AUTOSAR XML (schema 4-2-2)
package /STELLANTIS/EPT/ASWCs
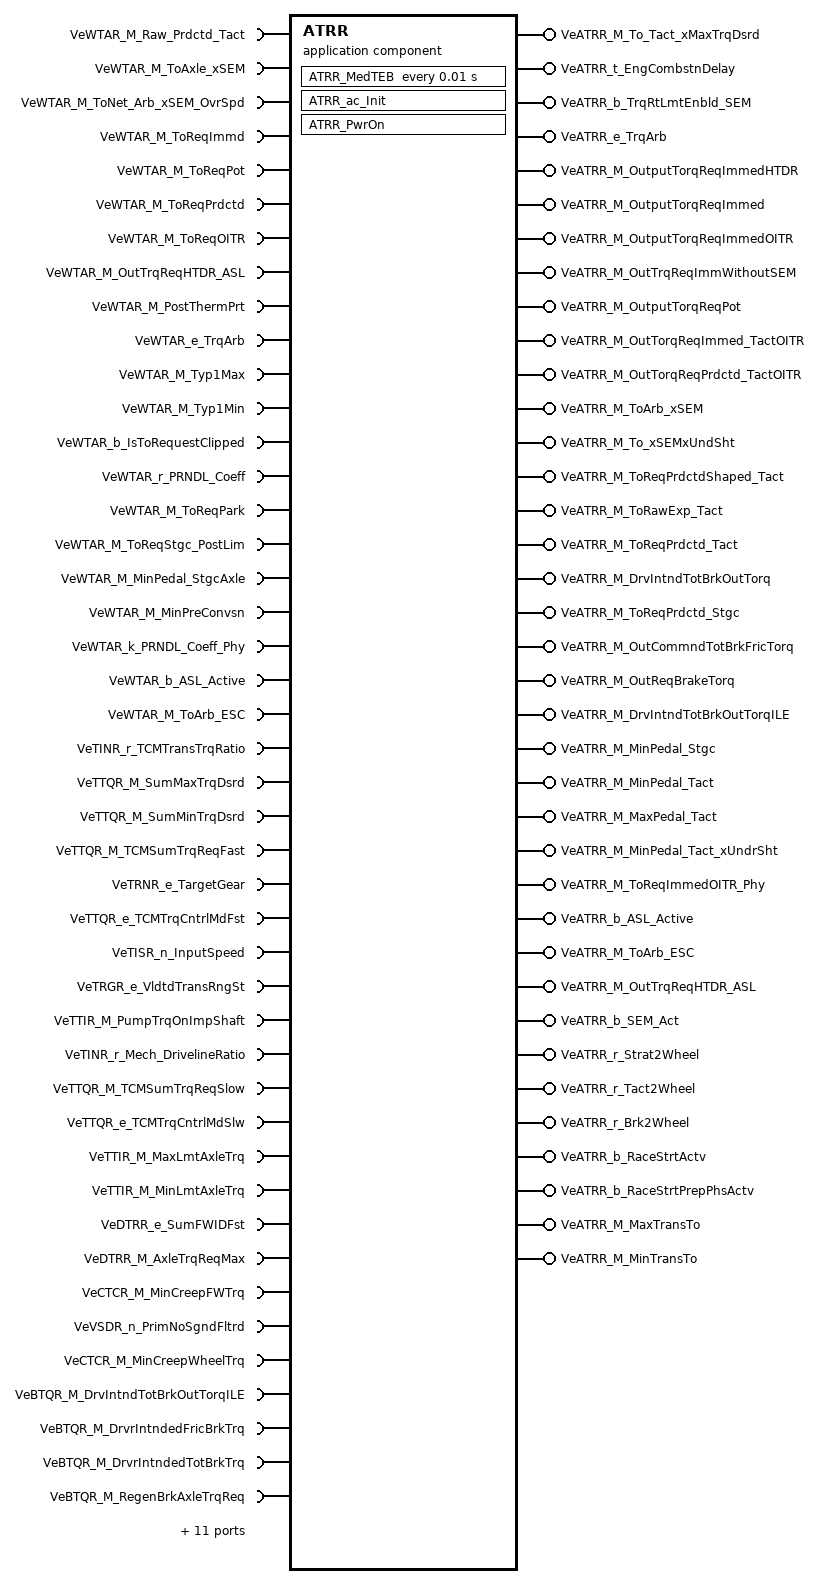
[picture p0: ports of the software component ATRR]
  application sw component type ATRR
    50 x require port:
      VeWTAR_M_Raw_Prdctd_Tact: nonqueued-receiver-com-spec{data-element=Value, init-value=0}, required-interface=VeWTAR_M_Raw_Prdctd_Tact
      VeWTAR_M_ToAxle_xSEM: nonqueued-receiver-com-spec{data-element=Value, init-value=0}, required-interface=VeWTAR_M_ToAxle_xSEM
      VeWTAR_M_ToNet_Arb_xSEM_OvrSpd: nonqueued-receiver-com-spec{data-element=Value, init-value=0}, required-interface=VeWTAR_M_ToNet_Arb_xSEM_OvrSpd
      VeWTAR_M_ToReqImmd: nonqueued-receiver-com-spec{data-element=Value, init-value=0}, required-interface=VeWTAR_M_ToReqImmd
      VeWTAR_M_ToReqPot: nonqueued-receiver-com-spec{data-element=Value, init-value=0}, required-interface=VeWTAR_M_ToReqPot
      VeWTAR_M_ToReqPrdctd: nonqueued-receiver-com-spec{data-element=Value, init-value=0}, required-interface=VeWTAR_M_ToReqPrdctd
      VeWTAR_M_ToReqOITR: nonqueued-receiver-com-spec{data-element=Value, init-value=0}, required-interface=VeWTAR_M_ToReqOITR
      VeWTAR_M_OutTrqReqHTDR_ASL: nonqueued-receiver-com-spec{data-element=Value, init-value=0}, required-interface=VeWTAR_M_OutTrqReqHTDR_ASL
      VeWTAR_M_PostThermPrt: nonqueued-receiver-com-spec{data-element=Value, init-value=0}, required-interface=VeWTAR_M_PostThermPrt
      VeWTAR_e_TrqArb: nonqueued-receiver-com-spec{data-element=Value, init-value=CeWTAR_e_ECM_TorqReqst}, required-interface=VeWTAR_e_TrqArb
      VeWTAR_M_Typ1Max: nonqueued-receiver-com-spec{data-element=Value, init-value=0}, required-interface=VeWTAR_M_Typ1Max
      VeWTAR_M_Typ1Min: nonqueued-receiver-com-spec{data-element=Value, init-value=0}, required-interface=VeWTAR_M_Typ1Min
      VeWTAR_b_IsToRequestClipped: nonqueued-receiver-com-spec{data-element=Value, init-value=0}, required-interface=VeWTAR_b_IsToRequestClipped
      VeWTAR_r_PRNDL_Coeff: nonqueued-receiver-com-spec{data-element=Value, init-value=0}, required-interface=VeWTAR_r_PRNDL_Coeff
      VeWTAR_M_ToReqPark: nonqueued-receiver-com-spec{data-element=Value, init-value=0}, required-interface=VeWTAR_M_ToReqPark
      VeWTAR_M_ToReqStgc_PostLim: nonqueued-receiver-com-spec{data-element=Value, init-value=0}, required-interface=VeWTAR_M_ToReqStgc_PostLim
      VeWTAR_M_MinPedal_StgcAxle: nonqueued-receiver-com-spec{data-element=Value, init-value=0}, required-interface=VeWTAR_M_MinPedal_StgcAxle
      VeWTAR_M_MinPreConvsn: nonqueued-receiver-com-spec{data-element=Value, init-value=0}, required-interface=VeWTAR_M_MinPreConvsn
      VeWTAR_k_PRNDL_Coeff_Phy: nonqueued-receiver-com-spec{data-element=Value, init-value=0}, required-interface=VeWTAR_k_PRNDL_Coeff_Phy
      VeWTAR_b_ASL_Active: nonqueued-receiver-com-spec{data-element=Value, init-value=0}, required-interface=VeWTAR_b_ASL_Active
      VeWTAR_M_ToArb_ESC: nonqueued-receiver-com-spec{data-element=Value, init-value=0}, required-interface=VeWTAR_M_ToArb_ESC
      VeTINR_r_TCMTransTrqRatio: nonqueued-receiver-com-spec{data-element=Value, init-value=0}, required-interface=VeTINR_r_TCMTransTrqRatio
      VeTTQR_M_SumMaxTrqDsrd: nonqueued-receiver-com-spec{data-element=Value, init-value=0}, required-interface=VeTTQR_M_SumMaxTrqDsrd
      VeTTQR_M_SumMinTrqDsrd: nonqueued-receiver-com-spec{data-element=Value, init-value=0}, required-interface=VeTTQR_M_SumMinTrqDsrd
      VeTTQR_M_TCMSumTrqReqFast: nonqueued-receiver-com-spec{data-element=Value, init-value=0}, required-interface=VeTTQR_M_TCMSumTrqReqFast
      VeTRNR_e_TargetGear: nonqueued-receiver-com-spec{data-element=Value, init-value=CeTRNR_e_Neutral}, required-interface=VeTRNR_e_TargetGear
      VeTTQR_e_TCMTrqCntrlMdFst: nonqueued-receiver-com-spec{data-element=Value, init-value=CeTINR_e_None}, required-interface=VeTTQR_e_TCMTrqCntrlMdFst
      VeTISR_n_InputSpeed: nonqueued-receiver-com-spec{data-element=Value, init-value=0}, required-interface=VeTISR_n_InputSpeed
      VeTRGR_e_VldtdTransRngSt: nonqueued-receiver-com-spec{data-element=Value, init-value=CeTRGR_e_NoSelectionAvailable}, required-interface=VeTRGR_e_VldtdTransRngSt
      VeTTIR_M_PumpTrqOnImpShaft: nonqueued-receiver-com-spec{data-element=Value, init-value=0}, required-interface=VeTTIR_M_PumpTrqOnImpShaft
      VeTINR_r_Mech_DrivelineRatio: nonqueued-receiver-com-spec{data-element=Value, init-value=0}, required-interface=VeTINR_r_Mech_DrivelineRatio
      VeTTQR_M_TCMSumTrqReqSlow: nonqueued-receiver-com-spec{data-element=Value, init-value=0}, required-interface=VeTTQR_M_TCMSumTrqReqSlow
      VeTTQR_e_TCMTrqCntrlMdSlw: nonqueued-receiver-com-spec{data-element=Value, init-value=CeTINR_e_None}, required-interface=VeTTQR_e_TCMTrqCntrlMdSlw
      VeTTIR_M_MaxLmtAxleTrq: nonqueued-receiver-com-spec{data-element=Value, init-value=0}, required-interface=VeTTIR_M_MaxLmtAxleTrq
      VeTTIR_M_MinLmtAxleTrq: nonqueued-receiver-com-spec{data-element=Value, init-value=0}, required-interface=VeTTIR_M_MinLmtAxleTrq
      VeDTRR_e_SumFWIDFst: nonqueued-receiver-com-spec{data-element=Value, init-value=CeDTRR_e_Potential}, required-interface=VeDTRR_e_SumFWIDFst
      VeDTRR_M_AxleTrqReqMax: nonqueued-receiver-com-spec{data-element=Value, init-value=0}, required-interface=VeDTRR_M_AxleTrqReqMax
      VeCTCR_M_MinCreepFWTrq: nonqueued-receiver-com-spec{data-element=Value, init-value=0}, required-interface=VeCTCR_M_MinCreepFWTrq
      VeVSDR_n_PrimNoSgndFltrd: nonqueued-receiver-com-spec{data-element=Value, init-value=0}, required-interface=VeVSDR_n_PrimNoSgndFltrd
      VeCTCR_M_MinCreepWheelTrq: nonqueued-receiver-com-spec{data-element=Value, init-value=0}, required-interface=VeCTCR_M_MinCreepWheelTrq
      VeBTQR_M_DrvIntndTotBrkOutTorqILE: nonqueued-receiver-com-spec{data-element=Value, init-value=0}, required-interface=VeBTQR_M_DrvIntndTotBrkOutTorqILE
      VeBTQR_M_DrvrIntndedFricBrkTrq: nonqueued-receiver-com-spec{data-element=Value, init-value=0}, required-interface=VeBTQR_M_DrvrIntndedFricBrkTrq
      VeBTQR_M_DrvrIntndedTotBrkTrq: nonqueued-receiver-com-spec{data-element=Value, init-value=0}, required-interface=VeBTQR_M_DrvrIntndedTotBrkTrq
      VeBTQR_M_RegenBrkAxleTrqReq: nonqueued-receiver-com-spec{data-element=Value, init-value=0}, required-interface=VeBTQR_M_RegenBrkAxleTrqReq
      VeFWDR_r_TCaseRatio: nonqueued-receiver-com-spec{data-element=Value, init-value=0}, required-interface=VeFWDR_r_TCaseRatio
      VeFWDR_r_Axle_Ratio: nonqueued-receiver-com-spec{data-element=Value, init-value=0}, required-interface=VeFWDR_r_Axle_Ratio
      VeSCCR_M_OutputTorqueLimit: nonqueued-receiver-com-spec{data-element=Value, init-value=0}, required-interface=VeSCCR_M_OutputTorqueLimit
      VeSCCR_M_ESCSumMax: nonqueued-receiver-com-spec{data-element=Value, init-value=0}, required-interface=VeSCCR_M_ESCSumMax
      VeSCCR_M_ESCSumMin: nonqueued-receiver-com-spec{data-element=Value, init-value=0}, required-interface=VeSCCR_M_ESCSumMin
      VeCTCR_M_MinCreepFWTrqTgt: nonqueued-receiver-com-spec{data-element=Value, init-value=0}, required-interface=VeCTCR_M_MinCreepFWTrqTgt
    37 x provide port:
      VeATRR_M_To_Tact_xMaxTrqDsrd: nonqueued-sender-com-spec{data-element=Value, init-value=0}, provided-interface=VeATRR_M_To_Tact_xMaxTrqDsrd
      VeATRR_t_EngCombstnDelay: nonqueued-sender-com-spec{data-element=Value, init-value=0}, provided-interface=VeATRR_t_EngCombstnDelay
      VeATRR_b_TrqRtLmtEnbld_SEM: nonqueued-sender-com-spec{data-element=Value, init-value=0}, provided-interface=VeATRR_b_TrqRtLmtEnbld_SEM
      VeATRR_e_TrqArb: nonqueued-sender-com-spec{data-element=Value, init-value=CeWTAR_e_ECM_TorqReqst}, provided-interface=VeATRR_e_TrqArb
      VeATRR_M_OutputTorqReqImmedHTDR: nonqueued-sender-com-spec{data-element=Value, init-value=0}, provided-interface=VeATRR_M_OutputTorqReqImmedHTDR
      VeATRR_M_OutputTorqReqImmed: nonqueued-sender-com-spec{data-element=Value, init-value=0}, provided-interface=VeATRR_M_OutputTorqReqImmed
      VeATRR_M_OutputTorqReqImmedOITR: nonqueued-sender-com-spec{data-element=Value, init-value=0}, provided-interface=VeATRR_M_OutputTorqReqImmedOITR
      VeATRR_M_OutTrqReqImmWithoutSEM: nonqueued-sender-com-spec{data-element=Value, init-value=0}, provided-interface=VeATRR_M_OutTrqReqImmWithoutSEM
      VeATRR_M_OutputTorqReqPot: nonqueued-sender-com-spec{data-element=Value, init-value=0}, provided-interface=VeATRR_M_OutputTorqReqPot
      VeATRR_M_OutTorqReqImmed_TactOITR: nonqueued-sender-com-spec{data-element=Value, init-value=0}, provided-interface=VeATRR_M_OutTorqReqImmed_TactOITR
      VeATRR_M_OutTorqReqPrdctd_TactOITR: nonqueued-sender-com-spec{data-element=Value, init-value=0}, provided-interface=VeATRR_M_OutTorqReqPrdctd_TactOITR
      VeATRR_M_ToArb_xSEM: nonqueued-sender-com-spec{data-element=Value, init-value=0}, provided-interface=VeATRR_M_ToArb_xSEM
      VeATRR_M_To_xSEMxUndSht: nonqueued-sender-com-spec{data-element=Value, init-value=0}, provided-interface=VeATRR_M_To_xSEMxUndSht
      VeATRR_M_ToReqPrdctdShaped_Tact: nonqueued-sender-com-spec{data-element=Value, init-value=0}, provided-interface=VeATRR_M_ToReqPrdctdShaped_Tact
      VeATRR_M_ToRawExp_Tact: nonqueued-sender-com-spec{data-element=Value, init-value=0}, provided-interface=VeATRR_M_ToRawExp_Tact
      VeATRR_M_ToReqPrdctd_Tact: nonqueued-sender-com-spec{data-element=Value, init-value=0}, provided-interface=VeATRR_M_ToReqPrdctd_Tact
      VeATRR_M_DrvIntndTotBrkOutTorq: nonqueued-sender-com-spec{data-element=Value, init-value=0}, provided-interface=VeATRR_M_DrvIntndTotBrkOutTorq
      VeATRR_M_ToReqPrdctd_Stgc: nonqueued-sender-com-spec{data-element=Value, init-value=0}, provided-interface=VeATRR_M_ToReqPrdctd_Stgc
      VeATRR_M_OutCommndTotBrkFricTorq: nonqueued-sender-com-spec{data-element=Value, init-value=0}, provided-interface=VeATRR_M_OutCommndTotBrkFricTorq
      VeATRR_M_OutReqBrakeTorq: nonqueued-sender-com-spec{data-element=Value, init-value=0}, provided-interface=VeATRR_M_OutReqBrakeTorq
      VeATRR_M_DrvIntndTotBrkOutTorqILE: nonqueued-sender-com-spec{data-element=Value, init-value=0}, provided-interface=VeATRR_M_DrvIntndTotBrkOutTorqILE
      VeATRR_M_MinPedal_Stgc: nonqueued-sender-com-spec{data-element=Value, init-value=0}, provided-interface=VeATRR_M_MinPedal_Stgc
      VeATRR_M_MinPedal_Tact: nonqueued-sender-com-spec{data-element=Value, init-value=0}, provided-interface=VeATRR_M_MinPedal_Tact
      VeATRR_M_MaxPedal_Tact: nonqueued-sender-com-spec{data-element=Value, init-value=0}, provided-interface=VeATRR_M_MaxPedal_Tact
      VeATRR_M_MinPedal_Tact_xUndrSht: nonqueued-sender-com-spec{data-element=Value, init-value=0}, provided-interface=VeATRR_M_MinPedal_Tact_xUndrSht
      VeATRR_M_ToReqImmedOITR_Phy: nonqueued-sender-com-spec{data-element=Value, init-value=0}, provided-interface=VeATRR_M_ToReqImmedOITR_Phy
      VeATRR_b_ASL_Active: nonqueued-sender-com-spec{data-element=Value, init-value=0}, provided-interface=VeATRR_b_ASL_Active
      VeATRR_M_ToArb_ESC: nonqueued-sender-com-spec{data-element=Value, init-value=0}, provided-interface=VeATRR_M_ToArb_ESC
      VeATRR_M_OutTrqReqHTDR_ASL: nonqueued-sender-com-spec{data-element=Value, init-value=0}, provided-interface=VeATRR_M_OutTrqReqHTDR_ASL
      VeATRR_b_SEM_Act: nonqueued-sender-com-spec{data-element=Value, init-value=0}, provided-interface=VeATRR_b_SEM_Act
      VeATRR_r_Strat2Wheel: nonqueued-sender-com-spec{data-element=Value, init-value=0}, provided-interface=VeATRR_r_Strat2Wheel
      VeATRR_r_Tact2Wheel: nonqueued-sender-com-spec{data-element=Value, init-value=0}, provided-interface=VeATRR_r_Tact2Wheel
      VeATRR_r_Brk2Wheel: nonqueued-sender-com-spec{data-element=Value, init-value=0}, provided-interface=VeATRR_r_Brk2Wheel
      VeATRR_b_RaceStrtActv: nonqueued-sender-com-spec{data-element=Value, init-value=0}, provided-interface=VeATRR_b_RaceStrtActv
      VeATRR_b_RaceStrtPrepPhsActv: nonqueued-sender-com-spec{data-element=Value, init-value=0}, provided-interface=VeATRR_b_RaceStrtPrepPhsActv
      VeATRR_M_MaxTransTo: nonqueued-sender-com-spec{data-element=Value, init-value=0}, provided-interface=VeATRR_M_MaxTransTo
      VeATRR_M_MinTransTo: nonqueued-sender-com-spec{data-element=Value, init-value=0}, provided-interface=VeATRR_M_MinTransTo
    5 x require port:
      KaTSXR_r_TCMGearRatios: parameter-require-com-spec{init-value=KaTSXR_r_TCMGearRatios_KaTSXR_r_TCMGearRatios:[KaTSXR_r_TCMGearRatios_KaTSXR_r_TCMGearRatios_rt_Array_Float_13_1:1, KaTSXR_r_TCMGearRatios_KaTSXR_r_TCMGearRatios_rt_Array_Float_13_2:1, KaTSXR_r_TCMGearRatios_KaTSXR_r_TCMGearRatios_rt_Array_Float_13_3:1, KaTSXR_r_TCMGearRatios_KaTSXR_r_TCMGearRatios_rt_Array_Float_13_4:1, KaTSXR_r_TCMGearRatios_KaTSXR_r_TCMGearRatios_rt_Array_Float_13_5:1, KaTSXR_r_TCMGearRatios_KaTSXR_r_TCMGearRatios_rt_Array_Float_13_6:1, KaTSXR_r_TCMGearRatios_KaTSXR_r_TCMGearRatios_rt_Array_Float_13_7:1, KaTSXR_r_TCMGearRatios_KaTSXR_r_TCMGearRatios_rt_Array_Float_13_8:1, KaTSXR_r_TCMGearRatios_KaTSXR_r_TCMGearRatios_rt_Array_Float_13_9:1, KaTSXR_r_TCMGearRatios_KaTSXR_r_TCMGearRatios_rt_Array_Float_13_10:1, KaTSXR_r_TCMGearRatios_KaTSXR_r_TCMGearRatios_rt_Array_Float_13_11:1, KaTSXR_r_TCMGearRatios_KaTSXR_r_TCMGearRatios_rt_Array_Float_13_12:1, KaTSXR_r_TCMGearRatios_KaTSXR_r_TCMGearRatios_rt_Array_Float_13_13:1], parameter=KaTSXR_r_TCMGearRatios}, required-interface=KaTSXR_r_TCMGearRatios
      HeTSXR_e_All_StratToDomain: parameter-require-com-spec{init-value=CeTSXR_e_AxleDomain, parameter=HeTSXR_e_All_StratToDomain}, required-interface=HeTSXR_e_All_StratToDomain
      HeTSXR_e_All_TactToDomain: parameter-require-com-spec{init-value=CeTSXR_e_AxleDomain, parameter=HeTSXR_e_All_TactToDomain}, required-interface=HeTSXR_e_All_TactToDomain
      HeATRR_b_BSGConvByps: parameter-require-com-spec{init-value=HeATRR_b_BSGConvByps_HeATRR_b_BSGConvByps:0, parameter=HeATRR_b_BSGConvByps}, required-interface=HeATRR_b_BSGConvByps
      HeATRR_b_RTC_Enbl: parameter-require-com-spec{init-value=HeATRR_b_RTC_Enbl_HeATRR_b_RTC_Enbl:0, parameter=HeATRR_b_RTC_Enbl}, required-interface=HeATRR_b_RTC_Enbl
    behavior IB_ATRR: data-type-mapping=msADTtoIDTMapping, handle-termination-and-restart=NO-SUPPORT
      timing event Event_MedTEB: start-on-event=ATRR_MedTEB, period=0.01
      init event Event_ATRR_ac_Init: start-on-event=ATRR_ac_Init
      init event Event_PwrOn: start-on-event=ATRR_PwrOn
      runnable ATRR_ac_Init
        data-send-points:
          access OUT_VeATRR_e_TrqArb_Value: accessed-variable=VeATRR_e_TrqArb.Value
      runnable ATRR_MedTEB
        data-receive-point-by-arguments:
          50 x access:
            IN_VeBTQR_M_DrvIntndTotBrkOutTorqILE_Value: accessed-variable=VeBTQR_M_DrvIntndTotBrkOutTorqILE.Value
            IN_VeBTQR_M_DrvrIntndedFricBrkTrq_Value: accessed-variable=VeBTQR_M_DrvrIntndedFricBrkTrq.Value
            IN_VeBTQR_M_DrvrIntndedTotBrkTrq_Value: accessed-variable=VeBTQR_M_DrvrIntndedTotBrkTrq.Value
            IN_VeBTQR_M_RegenBrkAxleTrqReq_Value: accessed-variable=VeBTQR_M_RegenBrkAxleTrqReq.Value
            IN_VeCTCR_M_MinCreepFWTrq_Value: accessed-variable=VeCTCR_M_MinCreepFWTrq.Value
            IN_VeCTCR_M_MinCreepFWTrqTgt_Value: accessed-variable=VeCTCR_M_MinCreepFWTrqTgt.Value
            IN_VeCTCR_M_MinCreepWheelTrq_Value: accessed-variable=VeCTCR_M_MinCreepWheelTrq.Value
            IN_VeDTRR_M_AxleTrqReqMax_Value: accessed-variable=VeDTRR_M_AxleTrqReqMax.Value
            IN_VeDTRR_e_SumFWIDFst_Value: accessed-variable=VeDTRR_e_SumFWIDFst.Value
            IN_VeFWDR_r_Axle_Ratio_Value: accessed-variable=VeFWDR_r_Axle_Ratio.Value
            IN_VeFWDR_r_TCaseRatio_Value: accessed-variable=VeFWDR_r_TCaseRatio.Value
            IN_VeSCCR_M_ESCSumMax_Value: accessed-variable=VeSCCR_M_ESCSumMax.Value
            IN_VeSCCR_M_ESCSumMin_Value: accessed-variable=VeSCCR_M_ESCSumMin.Value
            IN_VeSCCR_M_OutputTorqueLimit_Value: accessed-variable=VeSCCR_M_OutputTorqueLimit.Value
            IN_VeTINR_r_Mech_DrivelineRatio_Value: accessed-variable=VeTINR_r_Mech_DrivelineRatio.Value
            IN_VeTINR_r_TCMTransTrqRatio_Value: accessed-variable=VeTINR_r_TCMTransTrqRatio.Value
            IN_VeTISR_n_InputSpeed_Value: accessed-variable=VeTISR_n_InputSpeed.Value
            IN_VeTRGR_e_VldtdTransRngSt_Value: accessed-variable=VeTRGR_e_VldtdTransRngSt.Value
            IN_VeTRNR_e_TargetGear_Value: accessed-variable=VeTRNR_e_TargetGear.Value
            IN_VeTTIR_M_MaxLmtAxleTrq_Value: accessed-variable=VeTTIR_M_MaxLmtAxleTrq.Value
            IN_VeTTIR_M_MinLmtAxleTrq_Value: accessed-variable=VeTTIR_M_MinLmtAxleTrq.Value
            IN_VeTTIR_M_PumpTrqOnImpShaft_Value: accessed-variable=VeTTIR_M_PumpTrqOnImpShaft.Value
            IN_VeTTQR_M_SumMaxTrqDsrd_Value: accessed-variable=VeTTQR_M_SumMaxTrqDsrd.Value
            IN_VeTTQR_M_SumMinTrqDsrd_Value: accessed-variable=VeTTQR_M_SumMinTrqDsrd.Value
            IN_VeTTQR_M_TCMSumTrqReqFast_Value: accessed-variable=VeTTQR_M_TCMSumTrqReqFast.Value
            IN_VeTTQR_M_TCMSumTrqReqSlow_Value: accessed-variable=VeTTQR_M_TCMSumTrqReqSlow.Value
            IN_VeTTQR_e_TCMTrqCntrlMdFst_Value: accessed-variable=VeTTQR_e_TCMTrqCntrlMdFst.Value
            IN_VeTTQR_e_TCMTrqCntrlMdSlw_Value: accessed-variable=VeTTQR_e_TCMTrqCntrlMdSlw.Value
            IN_VeVSDR_n_PrimNoSgndFltrd_Value: accessed-variable=VeVSDR_n_PrimNoSgndFltrd.Value
            IN_VeWTAR_M_MinPedal_StgcAxle_Value: accessed-variable=VeWTAR_M_MinPedal_StgcAxle.Value
            IN_VeWTAR_M_MinPreConvsn_Value: accessed-variable=VeWTAR_M_MinPreConvsn.Value
            IN_VeWTAR_M_OutTrqReqHTDR_ASL_Value: accessed-variable=VeWTAR_M_OutTrqReqHTDR_ASL.Value
            IN_VeWTAR_M_PostThermPrt_Value: accessed-variable=VeWTAR_M_PostThermPrt.Value
            IN_VeWTAR_M_Raw_Prdctd_Tact_Value: accessed-variable=VeWTAR_M_Raw_Prdctd_Tact.Value
            IN_VeWTAR_M_ToArb_ESC_Value: accessed-variable=VeWTAR_M_ToArb_ESC.Value
            IN_VeWTAR_M_ToAxle_xSEM_Value: accessed-variable=VeWTAR_M_ToAxle_xSEM.Value
            IN_VeWTAR_M_ToNet_Arb_xSEM_OvrSpd_Value: accessed-variable=VeWTAR_M_ToNet_Arb_xSEM_OvrSpd.Value
            IN_VeWTAR_M_ToReqImmd_Value: accessed-variable=VeWTAR_M_ToReqImmd.Value
            IN_VeWTAR_M_ToReqOITR_Value: accessed-variable=VeWTAR_M_ToReqOITR.Value
            IN_VeWTAR_M_ToReqPark_Value: accessed-variable=VeWTAR_M_ToReqPark.Value
            IN_VeWTAR_M_ToReqPot_Value: accessed-variable=VeWTAR_M_ToReqPot.Value
            IN_VeWTAR_M_ToReqPrdctd_Value: accessed-variable=VeWTAR_M_ToReqPrdctd.Value
            IN_VeWTAR_M_ToReqStgc_PostLim_Value: accessed-variable=VeWTAR_M_ToReqStgc_PostLim.Value
            IN_VeWTAR_M_Typ1Max_Value: accessed-variable=VeWTAR_M_Typ1Max.Value
            IN_VeWTAR_M_Typ1Min_Value: accessed-variable=VeWTAR_M_Typ1Min.Value
            IN_VeWTAR_b_ASL_Active_Value: accessed-variable=VeWTAR_b_ASL_Active.Value
            IN_VeWTAR_b_IsToRequestClipped_Value: accessed-variable=VeWTAR_b_IsToRequestClipped.Value
            IN_VeWTAR_e_TrqArb_Value: accessed-variable=VeWTAR_e_TrqArb.Value
            IN_VeWTAR_k_PRNDL_Coeff_Phy_Value: accessed-variable=VeWTAR_k_PRNDL_Coeff_Phy.Value
            IN_VeWTAR_r_PRNDL_Coeff_Value: accessed-variable=VeWTAR_r_PRNDL_Coeff.Value
        data-send-points:
          37 x access:
            OUT_VeATRR_M_OutTorqReqPrdctd_TactOITR_Value: accessed-variable=VeATRR_M_OutTorqReqPrdctd_TactOITR.Value
            OUT_VeATRR_M_OutputTorqReqImmedHTDR_Value: accessed-variable=VeATRR_M_OutputTorqReqImmedHTDR.Value
            OUT_VeATRR_M_OutputTorqReqImmed_Value: accessed-variable=VeATRR_M_OutputTorqReqImmed.Value
            OUT_VeATRR_M_OutputTorqReqImmedOITR_Value: accessed-variable=VeATRR_M_OutputTorqReqImmedOITR.Value
            OUT_VeATRR_M_OutTrqReqImmWithoutSEM_Value: accessed-variable=VeATRR_M_OutTrqReqImmWithoutSEM.Value
            OUT_VeATRR_M_OutputTorqReqPot_Value: accessed-variable=VeATRR_M_OutputTorqReqPot.Value
            OUT_VeATRR_M_OutTorqReqImmed_TactOITR_Value: accessed-variable=VeATRR_M_OutTorqReqImmed_TactOITR.Value
            OUT_VeATRR_M_DrvIntndTotBrkOutTorq_Value: accessed-variable=VeATRR_M_DrvIntndTotBrkOutTorq.Value
            OUT_VeATRR_M_MinPedal_Stgc_Value: accessed-variable=VeATRR_M_MinPedal_Stgc.Value
            OUT_VeATRR_M_To_Tact_xMaxTrqDsrd_Value: accessed-variable=VeATRR_M_To_Tact_xMaxTrqDsrd.Value
            OUT_VeATRR_t_EngCombstnDelay_Value: accessed-variable=VeATRR_t_EngCombstnDelay.Value
            OUT_VeATRR_b_TrqRtLmtEnbld_SEM_Value: accessed-variable=VeATRR_b_TrqRtLmtEnbld_SEM.Value
            OUT_VeATRR_M_ToArb_xSEM_Value: accessed-variable=VeATRR_M_ToArb_xSEM.Value
            OUT_VeATRR_M_To_xSEMxUndSht_Value: accessed-variable=VeATRR_M_To_xSEMxUndSht.Value
            OUT_VeATRR_M_ToReqPrdctdShaped_Tact_Value: accessed-variable=VeATRR_M_ToReqPrdctdShaped_Tact.Value
            OUT_VeATRR_M_ToRawExp_Tact_Value: accessed-variable=VeATRR_M_ToRawExp_Tact.Value
            OUT_VeATRR_M_ToReqPrdctd_Tact_Value: accessed-variable=VeATRR_M_ToReqPrdctd_Tact.Value
            OUT_VeATRR_M_ToReqPrdctd_Stgc_Value: accessed-variable=VeATRR_M_ToReqPrdctd_Stgc.Value
            OUT_VeATRR_M_OutCommndTotBrkFricTorq_Value: accessed-variable=VeATRR_M_OutCommndTotBrkFricTorq.Value
            OUT_VeATRR_M_OutReqBrakeTorq_Value: accessed-variable=VeATRR_M_OutReqBrakeTorq.Value
            OUT_VeATRR_M_DrvIntndTotBrkOutTorqILE_Value: accessed-variable=VeATRR_M_DrvIntndTotBrkOutTorqILE.Value
            OUT_VeATRR_M_MinPedal_Tact_Value: accessed-variable=VeATRR_M_MinPedal_Tact.Value
            OUT_VeATRR_M_MaxPedal_Tact_Value: accessed-variable=VeATRR_M_MaxPedal_Tact.Value
            OUT_VeATRR_M_MinPedal_Tact_xUndrSht_Value: accessed-variable=VeATRR_M_MinPedal_Tact_xUndrSht.Value
            OUT_VeATRR_M_ToReqImmedOITR_Phy_Value: accessed-variable=VeATRR_M_ToReqImmedOITR_Phy.Value
            OUT_VeATRR_b_ASL_Active_Value: accessed-variable=VeATRR_b_ASL_Active.Value
            OUT_VeATRR_M_ToArb_ESC_Value: accessed-variable=VeATRR_M_ToArb_ESC.Value
            OUT_VeATRR_M_OutTrqReqHTDR_ASL_Value: accessed-variable=VeATRR_M_OutTrqReqHTDR_ASL.Value
            OUT_VeATRR_b_SEM_Act_Value: accessed-variable=VeATRR_b_SEM_Act.Value
            OUT_VeATRR_r_Strat2Wheel_Value: accessed-variable=VeATRR_r_Strat2Wheel.Value
            OUT_VeATRR_r_Tact2Wheel_Value: accessed-variable=VeATRR_r_Tact2Wheel.Value
            OUT_VeATRR_r_Brk2Wheel_Value: accessed-variable=VeATRR_r_Brk2Wheel.Value
            OUT_VeATRR_b_RaceStrtActv_Value: accessed-variable=VeATRR_b_RaceStrtActv.Value
            OUT_VeATRR_b_RaceStrtPrepPhsActv_Value: accessed-variable=VeATRR_b_RaceStrtPrepPhsActv.Value
            OUT_VeATRR_e_TrqArb_Value: accessed-variable=VeATRR_e_TrqArb.Value
            OUT_VeATRR_M_MaxTransTo_Value: accessed-variable=VeATRR_M_MaxTransTo.Value
            OUT_VeATRR_M_MinTransTo_Value: accessed-variable=VeATRR_M_MinTransTo.Value
        5 x parameter access:
          CALPRM_HeATRR_b_BSGConvByps_HeATRR_b_BSGConvByps: accessed-parameter=HeATRR_b_BSGConvByps.HeATRR_b_BSGConvByps
          CALPRM_HeATRR_b_RTC_Enbl_HeATRR_b_RTC_Enbl: accessed-parameter=HeATRR_b_RTC_Enbl.HeATRR_b_RTC_Enbl
          CALPRM_HeTSXR_e_All_StratToDomain_HeTSXR_e_All_StratToDomain: accessed-parameter=HeTSXR_e_All_StratToDomain.HeTSXR_e_All_StratToDomain
          CALPRM_HeTSXR_e_All_TactToDomain_HeTSXR_e_All_TactToDomain: accessed-parameter=HeTSXR_e_All_TactToDomain.HeTSXR_e_All_TactToDomain
          CALPRM_KaTSXR_r_TCMGearRatios_KaTSXR_r_TCMGearRatios: accessed-parameter=KaTSXR_r_TCMGearRatios.KaTSXR_r_TCMGearRatios
      runnable ATRR_PwrOn
        data-send-points:
          37 x access:
            OUT_VeATRR_M_To_Tact_xMaxTrqDsrd_Value: accessed-variable=VeATRR_M_To_Tact_xMaxTrqDsrd.Value
            OUT_VeATRR_t_EngCombstnDelay_Value: accessed-variable=VeATRR_t_EngCombstnDelay.Value
            OUT_VeATRR_b_TrqRtLmtEnbld_SEM_Value: accessed-variable=VeATRR_b_TrqRtLmtEnbld_SEM.Value
            OUT_VeATRR_M_ToArb_xSEM_Value: accessed-variable=VeATRR_M_ToArb_xSEM.Value
            OUT_VeATRR_M_To_xSEMxUndSht_Value: accessed-variable=VeATRR_M_To_xSEMxUndSht.Value
            OUT_VeATRR_M_ToReqPrdctdShaped_Tact_Value: accessed-variable=VeATRR_M_ToReqPrdctdShaped_Tact.Value
            OUT_VeATRR_M_ToRawExp_Tact_Value: accessed-variable=VeATRR_M_ToRawExp_Tact.Value
            OUT_VeATRR_M_ToReqPrdctd_Tact_Value: accessed-variable=VeATRR_M_ToReqPrdctd_Tact.Value
            OUT_VeATRR_M_ToReqPrdctd_Stgc_Value: accessed-variable=VeATRR_M_ToReqPrdctd_Stgc.Value
            OUT_VeATRR_M_OutCommndTotBrkFricTorq_Value: accessed-variable=VeATRR_M_OutCommndTotBrkFricTorq.Value
            OUT_VeATRR_M_OutReqBrakeTorq_Value: accessed-variable=VeATRR_M_OutReqBrakeTorq.Value
            OUT_VeATRR_M_DrvIntndTotBrkOutTorqILE_Value: accessed-variable=VeATRR_M_DrvIntndTotBrkOutTorqILE.Value
            OUT_VeATRR_M_MinPedal_Tact_Value: accessed-variable=VeATRR_M_MinPedal_Tact.Value
            OUT_VeATRR_M_MaxPedal_Tact_Value: accessed-variable=VeATRR_M_MaxPedal_Tact.Value
            OUT_VeATRR_M_MinPedal_Tact_xUndrSht_Value: accessed-variable=VeATRR_M_MinPedal_Tact_xUndrSht.Value
            OUT_VeATRR_M_ToReqImmedOITR_Phy_Value: accessed-variable=VeATRR_M_ToReqImmedOITR_Phy.Value
            OUT_VeATRR_b_ASL_Active_Value: accessed-variable=VeATRR_b_ASL_Active.Value
            OUT_VeATRR_M_ToArb_ESC_Value: accessed-variable=VeATRR_M_ToArb_ESC.Value
            OUT_VeATRR_M_OutTrqReqHTDR_ASL_Value: accessed-variable=VeATRR_M_OutTrqReqHTDR_ASL.Value
            OUT_VeATRR_b_SEM_Act_Value: accessed-variable=VeATRR_b_SEM_Act.Value
            OUT_VeATRR_r_Strat2Wheel_Value: accessed-variable=VeATRR_r_Strat2Wheel.Value
            OUT_VeATRR_r_Tact2Wheel_Value: accessed-variable=VeATRR_r_Tact2Wheel.Value
            OUT_VeATRR_r_Brk2Wheel_Value: accessed-variable=VeATRR_r_Brk2Wheel.Value
            OUT_VeATRR_b_RaceStrtActv_Value: accessed-variable=VeATRR_b_RaceStrtActv.Value
            OUT_VeATRR_b_RaceStrtPrepPhsActv_Value: accessed-variable=VeATRR_b_RaceStrtPrepPhsActv.Value
            OUT_VeATRR_M_MaxTransTo_Value: accessed-variable=VeATRR_M_MaxTransTo.Value
            OUT_VeATRR_M_MinTransTo_Value: accessed-variable=VeATRR_M_MinTransTo.Value
            OUT_VeATRR_e_TrqArb_Value: accessed-variable=VeATRR_e_TrqArb.Value
            OUT_VeATRR_M_OutTorqReqPrdctd_TactOITR_Value: accessed-variable=VeATRR_M_OutTorqReqPrdctd_TactOITR.Value
            OUT_VeATRR_M_OutputTorqReqImmedHTDR_Value: accessed-variable=VeATRR_M_OutputTorqReqImmedHTDR.Value
            OUT_VeATRR_M_OutputTorqReqImmed_Value: accessed-variable=VeATRR_M_OutputTorqReqImmed.Value
            OUT_VeATRR_M_OutputTorqReqImmedOITR_Value: accessed-variable=VeATRR_M_OutputTorqReqImmedOITR.Value
            OUT_VeATRR_M_OutTrqReqImmWithoutSEM_Value: accessed-variable=VeATRR_M_OutTrqReqImmWithoutSEM.Value
            OUT_VeATRR_M_OutputTorqReqPot_Value: accessed-variable=VeATRR_M_OutputTorqReqPot.Value
            OUT_VeATRR_M_OutTorqReqImmed_TactOITR_Value: accessed-variable=VeATRR_M_OutTorqReqImmed_TactOITR.Value
            OUT_VeATRR_M_DrvIntndTotBrkOutTorq_Value: accessed-variable=VeATRR_M_DrvIntndTotBrkOutTorq.Value
            OUT_VeATRR_M_MinPedal_Stgc_Value: accessed-variable=VeATRR_M_MinPedal_Stgc.Value
      variation point proxy Variant_ATRR_RTC_On: category=CONDITION, condition-access=0
      variation point proxy Variant_ATRR_RaceStart_Enabled: category=CONDITION, condition-access=0
